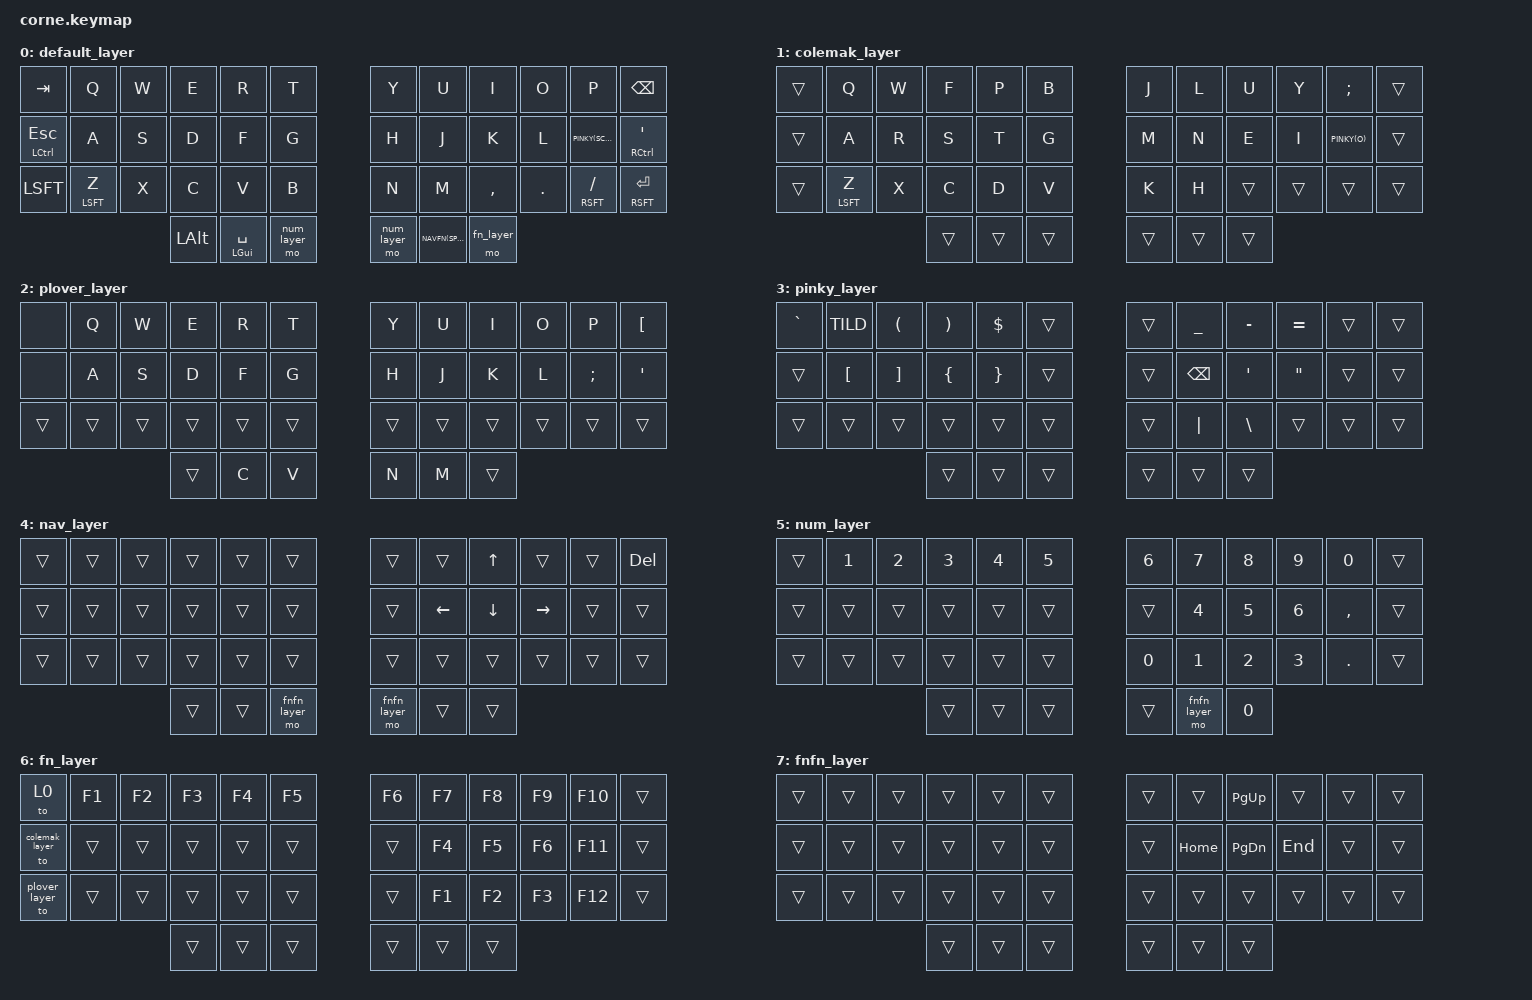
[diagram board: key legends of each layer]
/*
 * Copyright (c) 2020 The ZMK Contributors
 *
 * SPDX-License-Identifier: MIT
 */

#include <behaviors.dtsi>
#include <dt-bindings/zmk/keys.h>
#include <dt-bindings/zmk/bt.h>

/ {
	behaviors {
		ltp: behavior_layer_tap_permissive {
			compatible = "zmk,behavior-hold-tap";
			label = "LAYER_TAP_PERMISSIVE";
			#binding-cells = <2>;
			flavor = "balanced";
			tapping_term_ms = <200>;
			bindings = <&mo>, <&kp>;
		};
	};
};

/ {
    behaviors {
        mtp: bevavior_mod_tap_permissive {
            compatible = "zmk,behavior-hold-tap";
            label = "MOD_TAP_PERMISSIVE";
            #binding-cells = <2>;
            tapping_term_ms = <200>;
            flavor = "balanced";
            bindings = <&kp>, <&kp>;
        };
    };
};

#define _LMEH &mt LC(LA(LSFT))        TAB
#define _LHPR &mt LS(LC(LA(LSFT)))    TAB
#define _RMEH &mt RC(RA(RSFT))        BKSP
#define _RHPR &mt RS(RC(RA(RSFT)))    BKSP
#define _LCTL &mt LCTL ESC
#define _RCTL &mt RCTL SQT
#define _LSFT &mtp LSFT Z
#define _RSFT &mtp RSFT FSLH
#define _RET  &mt RSFT RET


#define QWERTY &to 0

#define colemak_layer 1
#define COLEMAK &to colemak_layer

#define plover_layer 2
#define PLOVER &to plover_layer

#define pinky_layer 3
#define PINKY(kp) &ltp pinky_layer kp

#define nav_layer 4
#define NAVFN(kp) &lt nav_layer kp

#define num_layer 5
#define NUMFN(kp) &lt num_layer kp

#define fn_layer 6
#define FN &mo fn_layer

#define fnfn_layer 7
#define FNFN &lt fnfn_layer kp

/ {
        keymap {
                compatible = "zmk,keymap";

                default_layer {
                        bindings = <
   &kp TAB  &kp Q &kp W &kp E &kp R &kp T   &kp Y &kp U &kp I    &kp O    &kp P       &kp BKSP
   _LCTL    &kp A &kp S &kp D &kp F &kp G   &kp H &kp J &kp K    &kp L    PINKY(SCLN) _RCTL
   &kp LSFT _LSFT &kp X &kp C &kp V &kp B   &kp N &kp M &kp CMMA &kp DOT  _RSFT       _RET
    &kp LALT  &mt LGUI SPC  &mo num_layer   &mo num_layer  NAVFN(SPC)  FN
                        >;
                };

                colemak_layer {
                        bindings = <
   &trans &kp Q &kp W &kp F &kp P &kp B   &kp J &kp L &kp U  &kp Y  &kp SCLN &trans
   &trans &kp A &kp R &kp S &kp T &kp G   &kp M &kp N &kp E  &kp I  PINKY(O) &trans
   &trans _LSFT &kp X &kp C &kp D &kp V   &kp K &kp H &trans &trans &trans   &trans
                 &trans  &trans  &trans   &trans  &trans  &trans
                        >;
                };

                plover_layer {
                        bindings = <
   &none  &kp Q  &kp W  &kp E  &kp R  &kp T    &kp Y  &kp U  &kp I  &kp O  &kp P    &kp LBKT
   &none  &kp A  &kp S  &kp D  &kp F  &kp G    &kp H  &kp J  &kp K  &kp L  &kp SCLN &kp QUOT
   &trans &trans &trans &trans &trans &trans   &trans &trans &trans &trans &trans   &trans
                        &trans  &kp C  &kp V   &kp N  &kp M  &trans
                        >;
                };

                pinky_layer {
                        bindings = <
   &kp GRAV &kp TILD &kp LPAR &kp RPAR &kp DLLR &trans   &trans &kp UNDER &kp MINUS &kp EQUAL &trans &trans
   &trans   &kp LBKT &kp RBKT &kp LBRC &kp RBRC &trans   &trans &kp BKSP  &kp SQT   &kp DQT   &trans &trans
   &trans   &trans   &trans   &trans   &trans   &trans   &trans &kp PIPE  &kp BSLH  &trans    &trans &trans
                                &trans  &trans  &trans   &trans  &trans  &trans
                        >;
                };

                nav_layer {
                        bindings = <
   &trans &trans &trans &trans &trans &trans     &trans &trans   &kp UP   &trans    &trans &kp DEL
   &trans &trans &trans &trans &trans &trans     &trans &kp LEFT &kp DOWN &kp RIGHT &trans &trans
   &trans &trans &trans &trans &trans &trans     &trans &trans   &trans   &trans    &trans &trans
              &trans  &trans  &mo fnfn_layer     &mo fnfn_layer  &trans  &trans
                        >;
                };

                num_layer {
                        bindings = <
   &trans &kp N1 &kp N2 &kp N3 &kp N4 &kp N5    &kp N6 &kp N7 &kp N8 &kp N9 &kp N0   &trans
   &trans &trans &trans &trans &trans &trans    &trans &kp N4 &kp N5 &kp N6 &kp CMMA &trans
   &trans &trans &trans &trans &trans &trans    &kp N0 &kp N1 &kp N2 &kp N3 &kp DOT  &trans
                      &trans  &trans  &trans    &trans  &mo fnfn_layer  &kp N0
                        >;
                };

                fn_layer {
                        bindings = <
   QWERTY   &kp F1   &kp F2   &kp F3   &kp F4   &kp F5     &kp F6   &kp F7   &kp F8   &kp F9   &kp F10  &trans
   COLEMAK  &trans   &trans   &trans   &trans   &trans     &trans   &kp F4   &kp F5   &kp F6   &kp F11  &trans
   PLOVER   &trans   &trans   &trans   &trans   &trans     &trans   &kp F1   &kp F2   &kp F3   &kp F12  &trans
                                  &trans &trans &trans     &trans &trans &trans
                        >;
                };

                fnfn_layer {
                        bindings = <
   &trans   &trans   &trans   &trans   &trans   &trans     &trans   &trans   &kp PG_UP &trans   &trans   &trans
   &trans   &trans   &trans   &trans   &trans   &trans     &trans   &kp HOME &kp PG_DN &kp END  &trans   &trans
   &trans   &trans   &trans   &trans   &trans   &trans     &trans   &trans   &trans    &trans   &trans   &trans
                                  &trans &trans &trans     &trans &trans &trans
                        >;
                };

/*
                empty_layer {
                        bindings = <
   &trans   &trans   &trans   &trans   &trans   &trans     &trans   &trans   &trans   &trans   &trans   &trans
   &trans   &trans   &trans   &trans   &trans   &trans     &trans   &trans   &trans   &trans   &trans   &trans
   &trans   &trans   &trans   &trans   &trans   &trans     &trans   &trans   &trans   &trans   &trans   &trans
                                  &trans &trans &trans     &trans &trans &trans
                        >;
                };
*/

        };
};

